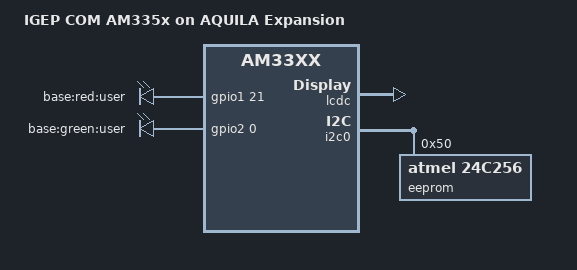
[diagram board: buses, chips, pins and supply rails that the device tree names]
#include "am335x-igep0033.dtsi"
/ {
	model = "IGEP COM AM335x on AQUILA Expansion";
	compatible = "isee,am335x-base0033", "isee,am335x-igep0033", "ti,am33xx";
	hdmi {
		compatible = "ti,tilcdc,slave";
		i2c = <&i2c0>;
		pinctrl-names = "default", "off";
		pinctrl-0 = <&nxp_hdmi_pins>;
		pinctrl-1 = <&nxp_hdmi_off_pins>;
		status = "okay";
	};
	leds_base {
		pinctrl-names = "default";
		pinctrl-0 = <&leds_base_pins>;
		compatible = "gpio-leds";
		led0 {
			label = "base:red:user";
			gpios = <&gpio1 21 GPIO_ACTIVE_HIGH>;	 
			default-state = "off";
		};
		led1 {
			label = "base:green:user";
			gpios = <&gpio2 0 GPIO_ACTIVE_HIGH>;	 
			default-state = "off";
		};
	};
};
&am33xx_pinmux {
	nxp_hdmi_pins: nxp-hdmi-pins {
		pinctrl-single,pins = <
			AM33XX_PADCONF(AM335X_PIN_XDMA_EVENT_INTR0, PIN_OUTPUT, MUX_MODE3)	 
			AM33XX_PADCONF(AM335X_PIN_LCD_DATA0, PIN_OUTPUT, MUX_MODE0)
			AM33XX_PADCONF(AM335X_PIN_LCD_DATA1, PIN_OUTPUT, MUX_MODE0)
			AM33XX_PADCONF(AM335X_PIN_LCD_DATA2, PIN_OUTPUT, MUX_MODE0)
			AM33XX_PADCONF(AM335X_PIN_LCD_DATA3, PIN_OUTPUT, MUX_MODE0)
			AM33XX_PADCONF(AM335X_PIN_LCD_DATA4, PIN_OUTPUT, MUX_MODE0)
			AM33XX_PADCONF(AM335X_PIN_LCD_DATA5, PIN_OUTPUT, MUX_MODE0)
			AM33XX_PADCONF(AM335X_PIN_LCD_DATA6, PIN_OUTPUT, MUX_MODE0)
			AM33XX_PADCONF(AM335X_PIN_LCD_DATA7, PIN_OUTPUT, MUX_MODE0)
			AM33XX_PADCONF(AM335X_PIN_LCD_DATA8, PIN_OUTPUT, MUX_MODE0)
			AM33XX_PADCONF(AM335X_PIN_LCD_DATA9, PIN_OUTPUT, MUX_MODE0)
			AM33XX_PADCONF(AM335X_PIN_LCD_DATA10, PIN_OUTPUT, MUX_MODE0)
			AM33XX_PADCONF(AM335X_PIN_LCD_DATA11, PIN_OUTPUT, MUX_MODE0)
			AM33XX_PADCONF(AM335X_PIN_LCD_DATA12, PIN_OUTPUT, MUX_MODE0)
			AM33XX_PADCONF(AM335X_PIN_LCD_DATA13, PIN_OUTPUT, MUX_MODE0)
			AM33XX_PADCONF(AM335X_PIN_LCD_DATA14, PIN_OUTPUT, MUX_MODE0)
			AM33XX_PADCONF(AM335X_PIN_LCD_DATA15, PIN_OUTPUT, MUX_MODE0)
			AM33XX_PADCONF(AM335X_PIN_LCD_VSYNC, PIN_OUTPUT, MUX_MODE0)
			AM33XX_PADCONF(AM335X_PIN_LCD_HSYNC, PIN_OUTPUT, MUX_MODE0)
			AM33XX_PADCONF(AM335X_PIN_LCD_PCLK, PIN_OUTPUT, MUX_MODE0)
			AM33XX_PADCONF(AM335X_PIN_LCD_AC_BIAS_EN, PIN_OUTPUT, MUX_MODE0)
		>;
	};
	nxp_hdmi_off_pins: nxp-hdmi-off-pins {
		pinctrl-single,pins = <
			AM33XX_PADCONF(AM335X_PIN_XDMA_EVENT_INTR0, PIN_OUTPUT, MUX_MODE3)	 
		>;
	};
	leds_base_pins: leds-base-pins {
		pinctrl-single,pins = <
			AM33XX_PADCONF(AM335X_PIN_GPMC_A5, PIN_OUTPUT_PULLDOWN, MUX_MODE7)	 
			AM33XX_PADCONF(AM335X_PIN_GPMC_CSN3, PIN_OUTPUT_PULLDOWN, MUX_MODE7)	 
		>;
	};
};
&lcdc {
	status = "okay";
};
&i2c0 {
	eeprom: eeprom@50 {
		compatible = "atmel,24c256";
		reg = <0x50>;
	};
};
